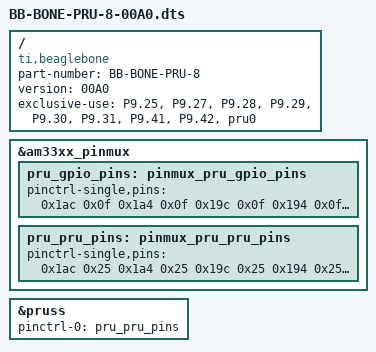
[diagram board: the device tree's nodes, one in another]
/dts-v1/;
/plugin/;

/ {
	compatible = "ti,beaglebone", "ti,beaglebone-black";

	/* identification */
	part-number = "BB-BONE-PRU-8";
	version = "00A0";

	/* state the resources this cape uses */
	exclusive-use =
		/* the pin header uses */
		"P9.25",	/* pru0: pr1_pru0_pru_r30_7 */
		"P9.27",	/* pru0: pr1_pru0_pru_r30_5 */
		"P9.28",	/* pru0: pr1_pru0_pru_r30_3 */
		"P9.29",	/* pru0: pr1_pru0_pru_r30_1 */
		"P9.30",	/* pru0: pr1_pru0_pru_r30_2 */
		"P9.31",	/* pru0: pr1_pru0_pru_r30_0 */
		"P9.41",	/* pru0: pr1_pru0_pru_r30_6 */
		"P9.42",	/* pru0: pr1_pru0_pru_r30_4 */
		/* the hardware IP uses */
		"pru0";

	fragment@0 {
		target = <&am33xx_pinmux>;
		__overlay__ {

			pru_gpio_pins: pinmux_pru_gpio_pins {
				pinctrl-single,pins = <
					0x1ac 0x0f 	/* P9 25 GPIO3_21: mcasp0_fsr.gpio3[21] | MODE7 | OUTPUT */
					0x1a4 0x0f 	/* P9 27 GPIO3_19: mcasp0_fsr.gpio3[19] | MODE7 | OUTPUT */
					0x19c 0x0f 	/* P9 28 GPIO3_17: mcasp0_fsr.gpio3[17] | MODE7 | OUTPUT */
					0x194 0x0f 	/* P9 29 GPIO3_15: mcasp0_fsr.gpio3[15] | MODE7 | OUTPUT */
					0x198 0x0f 	/* P9 30 GPIO3_16: mcasp0_fsr.gpio3[16] | MODE7 | OUTPUT */
					0x190 0x0f 	/* P9 31 GPIO3_14: mcasp0_fsr.gpio3[14] | MODE7 | OUTPUT */
					0x1a8 0x0f 	/* P9 41 GPIO3_20: mcasp0_fsr.gpio3[20] | MODE7 | OUTPUT */
					0x1a0 0x0f 	/* P9 42 GPIO3_18: mcasp0_fsr.gpio3[18] | MODE7 | OUTPUT */
				>;
			};

			pru_pru_pins: pinmux_pru_pru_pins {
				pinctrl-single,pins = <
					0x1ac 0x25	/* mcasp0_fsr.pr1_pru0_pru_r30_7, MODE5 | OUTPUT | PRU */
					0x1a4 0x25	/* mcasp0_fsr.pr1_pru0_pru_r30_5, MODE5 | OUTPUT | PRU */
					0x19c 0x25	/* mcasp0_fsr.pr1_pru0_pru_r30_3, MODE5 | OUTPUT | PRU */
					0x194 0x25	/* mcasp0_fsr.pr1_pru0_pru_r30_1, MODE5 | OUTPUT | PRU */
					0x198 0x25	/* mcasp0_fsr.pr1_pru0_pru_r30_2, MODE5 | OUTPUT | PRU */
					0x190 0x25	/* mcasp0_fsr.pr1_pru0_pru_r30_0, MODE5 | OUTPUT | PRU */
					0x1a8 0x25	/* mcasp0_fsr.pr1_pru0_pru_r30_6, MODE5 | OUTPUT | PRU */
					0x1a0 0x25	/* mcasp0_fsr.pr1_pru0_pru_r30_4, MODE5 | OUTPUT | PRU */
				>;
			};
		};	
	};

	fragment@2 {
		target = <&pruss>;
		__overlay__ {
			status = "okay";

			pinctrl-names = "default";
			pinctrl-0 = <&pru_pru_pins>;
		};
	};
};
